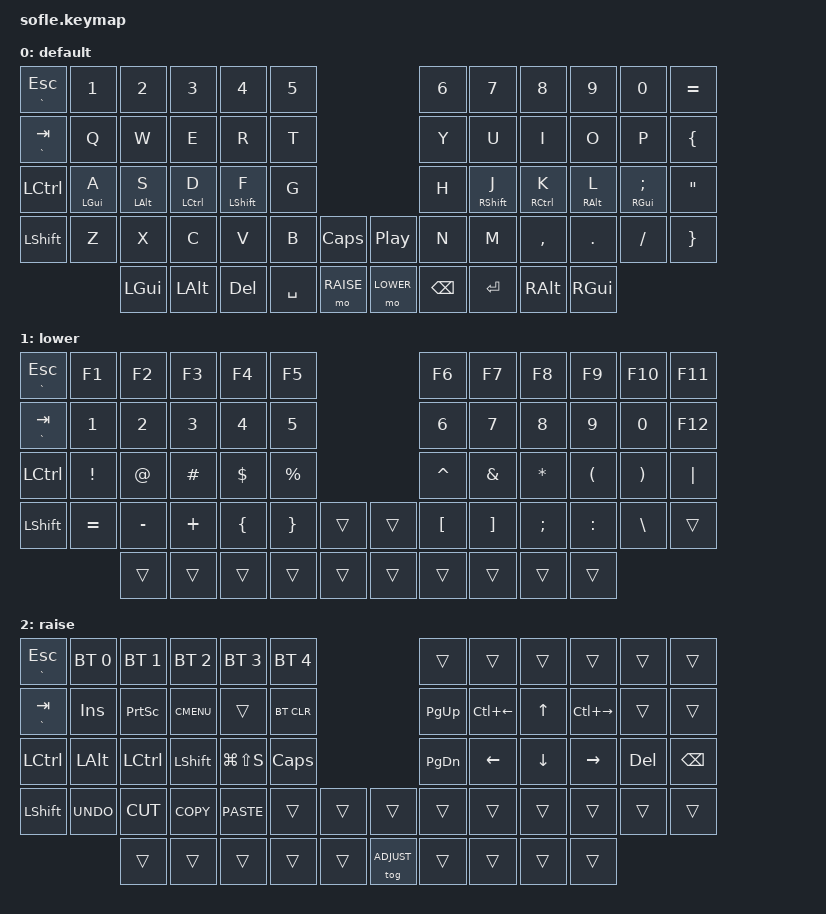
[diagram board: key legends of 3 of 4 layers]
/*
 * Copyright (c) 2020 The ZMK Contributors
 *
 * SPDX-License-Identifier: MIT
 */

#include <behaviors.dtsi>
#include <dt-bindings/zmk/keys.h>
#include <dt-bindings/zmk/bt.h>
#include <dt-bindings/zmk/rgb.h>
#include <dt-bindings/zmk/ext_power.h>
#include <dt-bindings/zmk/pointing.h>

#define BASE 0
#define LOWER 1
#define RAISE 2
#define ADJUST 3

/ {
    // conditional_layers {
    //     compatible = "zmk,conditional-layers";
    //     adjust_layer {
    //         if-layers = <LOWER RAISE>;
    //         then-layer = <ADJUST>;
    //     };
    // };

    behaviors {
        hml: home_row_mod_left {
            compatible = "zmk,behavior-hold-tap";
            #binding-cells = <2>;
            flavor = "balanced";
            require-prior-idle-ms = <150>;
            tapping-term-ms = <280>;
            quick-tap-ms = <175>;
            bindings = <&kp>, <&kp>;
            // hold-trigger-key-positions = < ... >; // List of keys on the right side of the keyboard
            // hold-trigger-on-release;
        };
        hmr: home_row_mod_right {
            compatible = "zmk,behavior-hold-tap";
            #binding-cells = <2>;
            flavor = "balanced";
            require-prior-idle-ms = <150>;
            tapping-term-ms = <280>;
            quick-tap-ms = <175>;
            bindings = <&kp>, <&kp>;
            // hold-trigger-key-positions = < ... >; // List of keys on the left side of the keyboard
            // hold-trigger-on-release;
        };

        // Defines a tap-preferred hold-tap (used for ESC/GRAVE and TAB/GRAVE)
        tp: tap_preferred {
            compatible = "zmk,behavior-hold-tap";
            #binding-cells = <2>;
            tapping-term-ms = <200>;
            flavor = "tap-preferred";
            bindings = <&kp>, <&kp>;
        };

        // Defines a hold-preferred hold-tap (used for your PSCRN / Snipping Tool combo)
        hp: hold_preferred {
            compatible = "zmk,behavior-hold-tap";
            #binding-cells = <2>;
            tapping-term-ms = <200>;
            flavor = "hold-preferred";
            bindings = <&kp>, <&kp>;
        };
    };

    keymap {
        compatible = "zmk,keymap";

        default_layer {
            display-name = "default";
// |   ESC   |   1!   |   2@   |   3#   |   4$   |   5%   |                                      |   6^   |   7&   |   8*   |   9(   |   0)   |   =+   |
// |   TAB   |   Q    |   W    |   E    |   R    |   T    |                                      |   Y    |   U    |   I    |   O    |   P    |   {[   |
// |  CTRL   | A(LG)  | S(ALT) | D(CT)  | F(SH)  |   G    |                                      |   H    | J(RSFT)| K(RCTL)| L(RALT)| ;(RG)  |   ""   |
// |  SHIFT  |   Z    |   X    |   C    |   V    |   B    |  PREV/NEXT/CAP  |  VOL+-/PLAY/PAUSE  |   N    |   M    |   ,    |   .    |   /    |   ]}   |
// |         |        |  LGUI  |  LALT  |  DEL   | SPACE  | RAISE  |                    | LOWER  |  BSPC  |  ENTER |  RALT  |  RGUI  |        |        |
            bindings = <
&tp GRAVE ESC &kp N1      &kp N2      &kp N3       &kp N4       &kp N5                                 &kp N6     &kp N7       &kp N8       &kp N9      &kp N0         &kp EQUAL
&tp GRAVE TAB &kp Q       &kp W       &kp E        &kp R        &kp T                                  &kp Y      &kp U        &kp I        &kp O       &kp P          &kp LBRC
&kp LCTRL     &hml LGUI A &hml LALT S &hml LCTRL D &hml LSHFT F &kp G                                  &kp H      &hmr RSHFT J &hmr RCTRL K &hmr RALT L &hmr RGUI SEMI &kp DQT
&kp LSHFT     &kp Z       &kp X       &kp C        &kp V        &kp B     &kp CAPS         &kp C_PP    &kp N      &kp M        &kp COMMA    &kp DOT     &kp FSLH       &kp RBRC
                          &kp LGUI    &kp LALT     &kp DEL      &kp SPACE &mo RAISE        &mo LOWER   &kp BSPC   &kp ENTER    &kp RALT     &kp RGUI
            >;
            sensor-bindings = <&inc_dec_kp C_PREV C_NEXT &inc_dec_kp C_VOL_DN C_VOL_UP>;
        };

        lower_layer {
            display-name = "lower";
// |   ESC   |   F1   |   F2   |   F3   |   F4   |   F5   |                          |   F6   |   F7   |   F8   |   F9   |   F10  |   F11  |
// |   TAB   |   1    |   2    |   3    |   4    |   5    |                          |   6    |   7    |   8    |   9    |   0    |   F12  |
// |  CTRL   |   !    |   @    |   #    |   $    |   %    |                          |   ^    |   &    |   *    |   (    |   )    |   |    |
// |  SHIFT  |   =    |   -    |   +    |   {    |   }    |        |        |        |   [    |   ]    |   ;    |   :    |   \    |        |
// |         |        |        |        |        |        |        |        |        |        |        |
            bindings = <
&tp GRAVE ESC &kp F1    &kp F2    &kp F3      &kp F4    &kp F5                    &kp F6    &kp F7   &kp F8    &kp F9    &kp F10   &kp F11
&tp GRAVE TAB &kp N1    &kp N2    &kp N3      &kp N4    &kp N5                    &kp N6    &kp N7   &kp N8    &kp N9    &kp N0    &kp F12
&kp LCTRL     &kp EXCL  &kp AT    &kp HASH    &kp DLLR  &kp PRCNT                 &kp CARET &kp AMPS &kp ASTRK &kp LPAR  &kp RPAR  &kp PIPE
&kp LSHFT     &kp EQUAL &kp MINUS &kp PLUS    &kp LBRC  &kp RBRC   &trans &trans  &kp LBKT  &kp RBKT &kp SEMI  &kp COLON &kp BSLH  &trans
                        &trans    &trans      &trans    &trans     &trans &trans  &trans    &trans   &trans    &trans
            >;
            sensor-bindings = <&inc_dec_kp C_PREV C_NEXT &inc_dec_kp C_VOL_DN C_VOL_UP>;
        };

        raise_layer {
            display-name = "raise";
// |   ESC   |  BT1   |  BT2   |  BT3   |  BT4   |  BT5   |                          |        |        |        |        |        |        |
// |   TAB   |  INS   |  PSCR  |  MENU  |        | BT_CLR |                          | PG UP  | PREV W |   UP   | NEXT W |        |        |
// |  CTRL   |  ALT   |  CTRL  |  SHIFT |  SS    |  CAPS  |                          | PG DN  |  LEFT  |  DOWN  | RIGHT  |  DEL   |  BSPC  |
// |  SHIFT  |  UNDO  |  CUT   |  COPY  | PASTE  |        |        |        |        |        |        |        |        |        |        |
// |         |        |        |        |        |        |        |        | ADJUST |        |        |
            bindings = <
&tp GRAVE ESC &bt BT_SEL 0 &bt BT_SEL 1 &bt BT_SEL 2 &bt BT_SEL 3  &bt BT_SEL 4                       &trans    &trans       &trans   &trans        &trans  &trans
&tp GRAVE TAB &kp INS      &kp PSCRN    &kp K_CMENU  &trans        &bt BT_CLR                         &kp PG_UP &kp LC(LEFT) &kp UP   &kp LC(RIGHT) &trans  &trans
&kp LCTRL     &kp LALT     &kp LCTRL    &kp LSHFT    &kp LG(LS(S)) &kp CLCK                           &kp PG_DN &kp LEFT     &kp DOWN &kp RIGHT     &kp DEL &kp BSPC
&kp LSHFT     &kp K_UNDO   &kp K_CUT    &kp K_COPY   &kp K_PASTE   &trans       &trans   &trans       &trans    &trans       &trans   &trans        &trans  &trans
                           &trans       &trans       &trans        &trans       &trans   &tog ADJUST  &trans    &trans       &trans   &trans
            >;
            sensor-bindings = <&inc_dec_kp C_PREV C_NEXT &inc_dec_kp C_VOL_DN C_VOL_UP>;
        };

        adjust_layer {
            display-name = "adjust";
// |   ESC   |   1!   |   2@   |   3#   |   4$   |   5%   |                          | BTCLR  |  BT1   |  BT2   |  BT3   |  BT4   |  BT5   |
// |   TAB   |   Q    |   W    |   E    |   R    |   T    |                          | EXTPWR | RGB_HUD| RGB_HUI| RGB_SAD| RGB_SAI| RGB_EFF|
// |  CTRL   |   A    |   S    |   D    |   F    |   G    |                          |        | RGB_BRD| RGB_BRI|        |        |        |
// |  SHIFT  |   Z    |   X    |   C    |   V    |   B    |        |        |        |        |        |        |        |        | RGB_TOG|
// |         |  LGUI  |  LALT  | SPACE  | RAISE  | ENTER  |        |        | ADJUST |        |        |        |        |
            bindings = <
&kp ESC    &kp N1     &kp N2     &kp N3     &kp N4     &kp N5                                      &bt BT_CLR        &bt BT_SEL 0    &bt BT_SEL 1    &bt BT_SEL 2    &bt BT_SEL 3    &bt BT_SEL 4
&kp TAB    &kp Q      &kp W      &kp E      &kp R      &kp T                                       &ext_power EP_TOG &rgb_ug RGB_HUD &rgb_ug RGB_HUI &rgb_ug RGB_SAD &rgb_ug RGB_SAI &rgb_ug RGB_EFF
&kp LCTRL  &kp A      &kp S      &kp D      &kp F      &kp G                                       &none             &rgb_ug RGB_BRD &rgb_ug RGB_BRI &none           &none           &none
&kp LSHFT  &kp Z      &kp X      &kp C      &kp V      &kp B      &kp C_MUTE        &kp C_PP       &none             &none           &none           &none           &none           &rgb_ug RGB_TOG
           &kp LGUI   &kp LALT   &kp SPACE  &mo RAISE  &kp ENTER  &none             &tog ADJUST    &none             &none           &none           &none
            >;
            sensor-bindings = <&inc_dec_kp C_PREV C_NEXT &inc_dec_kp C_VOL_DN C_VOL_UP>;
        };

    };
};
&left_encoder {
    resolution = <4>;
};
